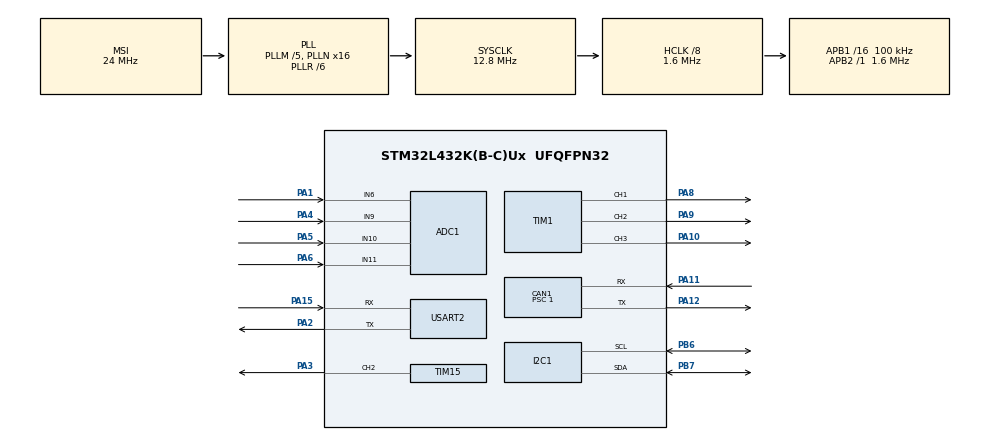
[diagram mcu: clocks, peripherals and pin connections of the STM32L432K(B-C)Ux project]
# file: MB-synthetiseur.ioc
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Mcu.Family=STM32L4
VP_SYS_VS_tim6.Mode=TIM6
RCC.CortexFreq_Value=1600000
NVIC.I2C1_EV_IRQn=true\:5\:0\:false\:false\:true\:true\:true\:true
I2C1.GeneralCallMode=I2C_GENERALCALL_DISABLE
NVIC.TIM6_DAC_IRQn=true\:0\:0\:false\:false\:true\:false\:false\:true
Dma.USART2_TX.1.MemInc=DMA_MINC_ENABLE
PA11.Mode=CAN_Activate
PA15\ (JTDI).Signal=USART2_RX
PC15-OSC32_OUT\ (PC15).Mode=LSE-External-Oscillator
RCC.SYSCLKSource=RCC_SYSCLKSOURCE_PLLCLK
ProjectManager.StackSize=0x400
VP_FREERTOS_VS_CMSIS_V2.Mode=CMSIS_V2
PC14-OSC32_IN\ (PC14).Mode=LSE-External-Oscillator
SH.S_TIM15_CH2.0=TIM15_CH2,PWM Generation2 CH2
PA15\ (JTDI).Mode=Asynchronous
PA12.Signal=CAN1_TX
Dma.USART2_RX.0.Priority=DMA_PRIORITY_LOW
NVIC.CAN1_TX_IRQn=true\:5\:0\:false\:false\:true\:true\:true\:true
Dma.USART2_RX.0.PeriphDataAlignment=DMA_PDATAALIGN_BYTE
RCC.HCLKFreq_Value=1600000
RCC.APB2TimFreq_Value=1600000
PB6.Signal=I2C1_SCL
Dma.USART2_TX.1.Mode=DMA_NORMAL
PB6.Mode=I2C
RCC.AHBFreq_Value=1600000
ADC1.Channel-0\#ChannelRegularConversion=ADC_CHANNEL_6
RCC.HSE_VALUE=16000000
USART2.VirtualMode-Asynchronous=VM_ASYNC
I2C1.NoStretchMode=I2C_NOSTRETCH_DISABLE
Dma.USART2_RX.0.MemDataAlignment=DMA_MDATAALIGN_BYTE
TIM1.Channel-PWM\ Generation1\ CH1=TIM_CHANNEL_1
TIM15.Channel-PWM\ Generation2\ CH2=TIM_CHANNEL_2
Dma.USART2_TX.1.Instance=DMA1_Channel7
FREERTOS.HEAP_NUMBER=2
PA0.Mode=HSE-External-Clock-Source-for-LittleOrca
Dma.USART2_RX.0.Instance=DMA1_Channel6
PB7.Signal=I2C1_SDA
PA8.Signal=S_TIM1_CH1
NVIC.I2C1_ER_IRQn=true\:5\:0\:false\:false\:true\:true\:true\:true
ADC1.SamplingTime-0\#ChannelRegularConversion=ADC_SAMPLETIME_2CYCLES_5
FREERTOS.configTOTAL_HEAP_SIZE=30000
PA0.Signal=RCC_CK_IN
CAN1.Prescaler=1
Mcu.Package=UFQFPN32
PA6.Signal=ADCx_IN11
NVIC.TimeBase=TIM6_DAC_IRQn
Dma.USART2_RX.0.PeriphInc=DMA_PINC_DISABLE
NVIC.TimeBaseIP=TIM6
PA10.Signal=S_TIM1_CH3
SH.ADCx_IN9.0=ADC1_IN9,IN9-Single-Ended
Dma.Request1=USART2_TX
RCC.APB1TimFreq_Value=200000
FREERTOS.configMAX_TASK_NAME_LEN=16
Dma.Request0=USART2_RX
CAN1.CalculateTimeBit=50000.00
RCC.MSIClockRange=RCC_MSIRANGE_9
RCC.HSI48_VALUE=48000000
RCC.PLLSAI1N=14
PA3.Signal=S_TIM15_CH2
CAN1.CalculateTimeQuantum=10000.0
RCC.MSI_VALUE=24000000
NVIC.DMA1_Channel6_IRQn=true\:5\:0\:false\:false\:true\:true\:false\:true
Dma.USART2_TX.1.Priority=DMA_PRIORITY_LOW
FREERTOS.Tasks01=defaultTask,24,128,StartDefaultTask,Default,NULL,Dynamic,NULL,NULL;readTempTask,8,128,StartReadTempTask,Default,NULL,Dynamic,NULL,NULL;readLightTask,8,128,StartReadLightTask,Default,NULL,Dynamic,NULL,NULL
ADC1.Rank-0\#ChannelRegularConversion=1
SH.ADCx_IN6.0=ADC1_IN6,IN6-Single-Ended
ADC1.OffsetNumber-0\#ChannelRegularConversion=ADC_OFFSET_NONE
CAN1.CalculateBaudRate=20000
Dma.USART2_RX.0.Direction=DMA_PERIPH_TO_MEMORY
PC15-OSC32_OUT\ (PC15).Signal=RCC_OSC32_OUT
RCC.APB1CLKDivider=RCC_HCLK_DIV16
Dma.USART2_TX.1.PeriphDataAlignment=DMA_PDATAALIGN_BYTE
Dma.USART2_RX.0.Mode=DMA_NORMAL
SH.S_TIM1_CH1.0=TIM1_CH1,PWM Generation1 CH1
CAN1.BS2=CAN_BS2_2TQ
CAN1.BS1=CAN_BS1_2TQ
ProjectManager.TargetToolchain=STM32CubeIDE
PA9.Signal=S_TIM1_CH2
TIM1.Channel-PWM\ Generation2\ CH2=TIM_CHANNEL_2
I2C1.Timing=0x00000000
RCC.USBFreq_Value=33600000
PA1.Signal=ADCx_IN6
PA5.Signal=ADCx_IN10
Dma.USART2_TX.1.PeriphInc=DMA_PINC_DISABLE
board=custom
RCC.VCOOutputFreq_Value=76800000
Dma.USART2_TX.1.Direction=DMA_MEMORY_TO_PERIPH
RCC.APB2Freq_Value=1600000
SH.ADCx_IN11.0=ADC1_IN11,IN11-Single-Ended
SH.S_TIM1_CH2.0=TIM1_CH2,PWM Generation2 CH2
RCC.ADCFreq_Value=33600000
RCC.AHBCLKDivider=RCC_SYSCLK_DIV8
Mcu.Name=STM32L432K(B-C)Ux
Dma.USART2_RX.0.MemInc=DMA_MINC_ENABLE
PA2.Signal=USART2_TX
CAN1.SJW=CAN_SJW_1TQ
PA4.Signal=ADCx_IN9
RCC.SYSCLKFreq_VALUE=12800000
ADC1.master=1
PA12.Mode=CAN_Activate
PC14-OSC32_IN\ (PC14).Signal=RCC_OSC32_IN
PB7.Mode=I2C
PA11.Signal=CAN1_RX
SH.ADCx_IN10.0=ADC1_IN10,IN10-Single-Ended
ProjectManager.HeapSize=0x200
SH.S_TIM1_CH3.0=TIM1_CH3,PWM Generation3 CH3
RCC.HSI_VALUE=16000000
NVIC.PriorityGroup=NVIC_PRIORITYGROUP_4
RCC.PLLR=RCC_PLLR_DIV6
ADC1.NbrOfConversionFlag=1
RCC.PLLM=5
RCC.PLLN=16
PA2.Mode=Asynchronous
RCC.USART2CLockSelection=RCC_USART2CLKSOURCE_SYSCLK
NVIC.DMA1_Channel7_IRQn=true\:5\:0\:false\:false\:true\:true\:false\:true
Dma.USART2_TX.1.MemDataAlignment=DMA_MDATAALIGN_BYTE
TIM1.Channel-PWM\ Generation3\ CH3=TIM_CHANNEL_3
RCC.APB1Freq_Value=100000
NVIC.CAN1_RX0_IRQn=true\:5\:0\:false\:false\:true\:true\:true\:true

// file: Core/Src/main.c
/* USER CODE BEGIN Header */
/**
  ******************************************************************************
  * @file           : main.c
  * @brief          : Main program body
  ******************************************************************************
  * @attention
  *
  * <h2><center>&copy; Copyright (c) 2021 STMicroelectronics.
  * All rights reserved.</center></h2>
  *
  * This software component is licensed by ST under Ultimate Liberty license
  * SLA0044, the "License"; You may not use this file except in compliance with
  * the License. You may obtain a copy of the License at:
  *                             www.st.com/SLA0044
  *
  ******************************************************************************
  */
/* USER CODE END Header */
#include "main.h"
#include "cmsis_os.h"
#include "adc.h"
#include "can.h"
#include "dma.h"
#include "i2c.h"
#include "tim.h"
#include "usart.h"
#include "gpio.h"

/* USER CODE BEGIN Includes */
#include <string.h>

#include <AS7341.h>
#include <MCP9600.h>
#include <PCA9685.h>
#include <INA226.h>

/* USER CODE END Includes */

/* USER CODE BEGIN PV */
/*
CAN_FilterTypeDef sFilterConfig;
CAN_TxHeaderTypeDef TxHeader;
CAN_RxHeaderTypeDef RxHeader;
uint8_t TxData[8]={1,2,3,4,5,6,7,8};
uint8_t RxData[8];
uint32_t TxMailbox;

typedef struct {
  uint8_t ID;
  uint8_t TH;
  uint8_t TC;
  uint8_t TD;
  uint16_t CH1to3[3];
  uint16_t CH4to5[3];
  uint16_t CH6to8[3];
} canPacketStruct;
*/
/* USER CODE END PV */

void SystemClock_Config(void);
void MX_FREERTOS_Init(void);

int main(void)
{
  /* USER CODE BEGIN 1 */
	//UNSIGNED8	emcyData[5] = { 1, 2, 3, 4, 5 };

  /* USER CODE END 1 */

  /* MCU Configuration--------------------------------------------------------*/

  /* Reset of all peripherals, Initializes the Flash interface and the Systick. */
  HAL_Init();

  /* USER CODE BEGIN Init */
  //uint8_t I2C_address = 0x80;
  //pca9685_init(&hi2c3, I2C_address);
  /* USER CODE END Init */

  /* Configure the system clock */
  SystemClock_Config();

  /* Initialize all configured peripherals */
  MX_GPIO_Init();
  MX_DMA_Init();
  MX_I2C1_Init();
  MX_CAN1_Init();
  MX_TIM1_Init();
  MX_ADC1_Init();
  MX_TIM15_Init();
  MX_USART2_UART_Init();
  /* USER CODE BEGIN 2 */
  /*
	  PCA9685begin(hi2c1,0);
	  pca9685_init(0x80);
	  RxData[0]=8;
	  RxData[1]=0;

  sFilterConfig.FilterBank = 0;
  sFilterConfig.FilterMode = CAN_FILTERMODE_IDMASK;
  sFilterConfig.FilterScale = CAN_FILTERSCALE_32BIT;
  sFilterConfig.FilterIdHigh = 0x033<<5;
  sFilterConfig.FilterIdLow = 0x0000;
  sFilterConfig.FilterMaskIdHigh = 0x0000;
  sFilterConfig.FilterMaskIdLow = 0x0000;
  sFilterConfig.FilterFIFOAssignment = CAN_RX_FIFO0;
  sFilterConfig.FilterActivation = ENABLE;
  sFilterConfig.SlaveStartFilterBank = 14;

  if (HAL_CAN_ConfigFilter(&hcan1, &sFilterConfig) != HAL_OK)
  {
	  Error_Handler();
  }

  if (HAL_CAN_Start(&hcan1) != HAL_OK)
  {

	  Error_Handler();
  }

  if (HAL_CAN_ActivateNotification(&hcan1, CAN_IT_RX_FIFO0_OVERRUN) != HAL_OK)
  {

	  Error_Handler();
  }
  if (HAL_CAN_ActivateNotification(&hcan1, CAN_IT_TX_MAILBOX_EMPTY) != HAL_OK)
  {

	  Error_Handler();
  }
  if (HAL_CAN_ActivateNotification(&hcan1, CAN_IT_RX_FIFO0_MSG_PENDING) != HAL_OK)
  {

	  Error_Handler();
  }
  TxHeader.StdId = 0x07; //07
  //TxHeader.ExtId = 0x01; //delete
  TxHeader.RTR = CAN_RTR_DATA;
  TxHeader.IDE = CAN_ID_STD;
  TxHeader.DLC = 8;
  TxHeader.TransmitGlobalTime = DISABLE;

*/

  /* USER CODE END 2 */

  /* Init scheduler */
  osKernelInitialize();  /* Call init function for freertos objects (in freertos.c) */
  MX_FREERTOS_Init();
  /* Start scheduler */
  osKernelStart();

  /* We should never get here as control is now taken by the scheduler */
  /* Infinite loop */
  while (1)
  {

  }
}

void SystemClock_Config(void)
{
  RCC_OscInitTypeDef RCC_OscInitStruct = {0};
  RCC_ClkInitTypeDef RCC_ClkInitStruct = {0};
  RCC_PeriphCLKInitTypeDef PeriphClkInit = {0};

  /** Configure LSE Drive Capability
  */
  HAL_PWR_EnableBkUpAccess();
  __HAL_RCC_LSEDRIVE_CONFIG(RCC_LSEDRIVE_LOW);
  /** Initializes the RCC Oscillators according to the specified parameters
  * in the RCC_OscInitTypeDef structure.
  */
  RCC_OscInitStruct.OscillatorType = RCC_OSCILLATORTYPE_LSE|RCC_OSCILLATORTYPE_MSI;
  RCC_OscInitStruct.LSEState = RCC_LSE_ON;
  RCC_OscInitStruct.MSIState = RCC_MSI_ON;
  RCC_OscInitStruct.MSICalibrationValue = 0;
  RCC_OscInitStruct.MSIClockRange = RCC_MSIRANGE_9;
  RCC_OscInitStruct.PLL.PLLState = RCC_PLL_ON;
  RCC_OscInitStruct.PLL.PLLSource = RCC_PLLSOURCE_MSI;
  RCC_OscInitStruct.PLL.PLLM = 5;
  RCC_OscInitStruct.PLL.PLLN = 16;
  RCC_OscInitStruct.PLL.PLLP = RCC_PLLP_DIV7;
  RCC_OscInitStruct.PLL.PLLQ = RCC_PLLQ_DIV2;
  RCC_OscInitStruct.PLL.PLLR = RCC_PLLR_DIV6;
  if (HAL_RCC_OscConfig(&RCC_OscInitStruct) != HAL_OK)
  {
    Error_Handler();
  }
  /** Initializes the CPU, AHB and APB buses clocks
  */
  RCC_ClkInitStruct.ClockType = RCC_CLOCKTYPE_HCLK|RCC_CLOCKTYPE_SYSCLK
                              |RCC_CLOCKTYPE_PCLK1|RCC_CLOCKTYPE_PCLK2;
  RCC_ClkInitStruct.SYSCLKSource = RCC_SYSCLKSOURCE_PLLCLK;
  RCC_ClkInitStruct.AHBCLKDivider = RCC_SYSCLK_DIV8;
  RCC_ClkInitStruct.APB1CLKDivider = RCC_HCLK_DIV16;
  RCC_ClkInitStruct.APB2CLKDivider = RCC_HCLK_DIV1;

  if (HAL_RCC_ClockConfig(&RCC_ClkInitStruct, FLASH_LATENCY_0) != HAL_OK)
  {
    Error_Handler();
  }
  PeriphClkInit.PeriphClockSelection = RCC_PERIPHCLK_USART2|RCC_PERIPHCLK_I2C1
                              |RCC_PERIPHCLK_ADC;
  PeriphClkInit.Usart2ClockSelection = RCC_USART2CLKSOURCE_SYSCLK;
  PeriphClkInit.I2c1ClockSelection = RCC_I2C1CLKSOURCE_PCLK1;
  PeriphClkInit.AdcClockSelection = RCC_ADCCLKSOURCE_PLLSAI1;
  PeriphClkInit.PLLSAI1.PLLSAI1Source = RCC_PLLSOURCE_MSI;
  PeriphClkInit.PLLSAI1.PLLSAI1M = 5;
  PeriphClkInit.PLLSAI1.PLLSAI1N = 14;
  PeriphClkInit.PLLSAI1.PLLSAI1P = RCC_PLLP_DIV7;
  PeriphClkInit.PLLSAI1.PLLSAI1Q = RCC_PLLQ_DIV2;
  PeriphClkInit.PLLSAI1.PLLSAI1R = RCC_PLLR_DIV2;
  PeriphClkInit.PLLSAI1.PLLSAI1ClockOut = RCC_PLLSAI1_ADC1CLK;
  if (HAL_RCCEx_PeriphCLKConfig(&PeriphClkInit) != HAL_OK)
  {
    Error_Handler();
  }
  /** Configure the main internal regulator output voltage
  */
  if (HAL_PWREx_ControlVoltageScaling(PWR_REGULATOR_VOLTAGE_SCALE1) != HAL_OK)
  {
    Error_Handler();
  }
  /** Enable MSI Auto calibration
  */
  HAL_RCCEx_EnableMSIPLLMode();
}

/* USER CODE BEGIN 4 */

/**
  * @brief  Rx Fifo 0 message pending callback
  * @param  hcan: pointer to a CAN_HandleTypeDef structure that contains
  *         the configuration information for the specified CAN.
  * @retval None
  */

/* USER CODE END 4 */

 /**
  * @brief  Period elapsed callback in non blocking mode
  * @note   This function is called  when TIM6 interrupt took place, inside
  * HAL_TIM_IRQHandler(). It makes a direct call to HAL_IncTick() to increment
  * a global variable "uwTick" used as application time base.
  * @param  htim : TIM handle
  * @retval None
  */
void HAL_TIM_PeriodElapsedCallback(TIM_HandleTypeDef *htim)
{
  if (htim->Instance == TIM6) {
    HAL_IncTick();
  }
}

void Error_Handler(void)
{
  /* USER CODE BEGIN Error_Handler_Debug */
  /* User can add his own implementation to report the HAL error return state */
  //__disable_irq();
  while (1)
  {
  }
  /* USER CODE END Error_Handler_Debug */
}

/************************ (C) COPYRIGHT STMicroelectronics *****END OF FILE****/

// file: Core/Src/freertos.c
/* USER CODE BEGIN Header */
/**
  ******************************************************************************
  * File Name          : freertos.c
  * Description        : Code for freertos applications
  ******************************************************************************
  * @attention
  *
  * <h2><center>&copy; Copyright (c) 2021 STMicroelectronics.
  * All rights reserved.</center></h2>
  *
  * This software component is licensed by ST under Ultimate Liberty license
  * SLA0044, the "License"; You may not use this file except in compliance with
  * the License. You may obtain a copy of the License at:
  *                             www.st.com/SLA0044
  *
  ******************************************************************************
  */
/* USER CODE END Header */

#include "FreeRTOS.h"
#include "task.h"
#include "main.h"
#include "cmsis_os.h"

/* Definitions for defaultTask */
osThreadId_t defaultTaskHandle;
const osThreadAttr_t defaultTask_attributes = {
  .name = "defaultTask",
  .stack_size = 128 * 4,
  .priority = (osPriority_t) osPriorityNormal,
};
/* Definitions for readTempTask */
osThreadId_t readTempTaskHandle;
const osThreadAttr_t readTempTask_attributes = {
  .name = "readTempTask",
  .stack_size = 128 * 4,
  .priority = (osPriority_t) osPriorityLow,
};
/* Definitions for readLightTask */
osThreadId_t readLightTaskHandle;
const osThreadAttr_t readLightTask_attributes = {
  .name = "readLightTask",
  .stack_size = 128 * 4,
  .priority = (osPriority_t) osPriorityLow,
};

void StartDefaultTask(void *argument);
void StartReadTempTask(void *argument);
void StartReadLightTask(void *argument);

void MX_FREERTOS_Init(void); /* (MISRA C 2004 rule 8.1) */

void MX_FREERTOS_Init(void) {

  /* Create the thread(s) */
  /* creation of defaultTask */
  defaultTaskHandle = osThreadNew(StartDefaultTask, NULL, &defaultTask_attributes);

  /* creation of readTempTask */
  readTempTaskHandle = osThreadNew(StartReadTempTask, NULL, &readTempTask_attributes);

  /* creation of readLightTask */
  readLightTaskHandle = osThreadNew(StartReadLightTask, NULL, &readLightTask_attributes);

}

void StartDefaultTask(void *argument)
{
  /* USER CODE BEGIN StartDefaultTask */
  /* Infinite loop */
  for(;;)
  {
	  //spectro();
	  programStart();
  }
  /* USER CODE END StartDefaultTask */
}

void StartReadTempTask(void *argument)
{
  /* USER CODE BEGIN StartReadTempTask */
  /* Infinite loop */
  for(;;)
  {
	  //osDelay(1);
	  //program1ms();
  }
  /* USER CODE END StartReadTempTask */
}

void StartReadLightTask(void *argument)
{
  for(;;)
  {
    osDelay(1);
  }
}

/************************ (C) COPYRIGHT STMicroelectronics *****END OF FILE****/
